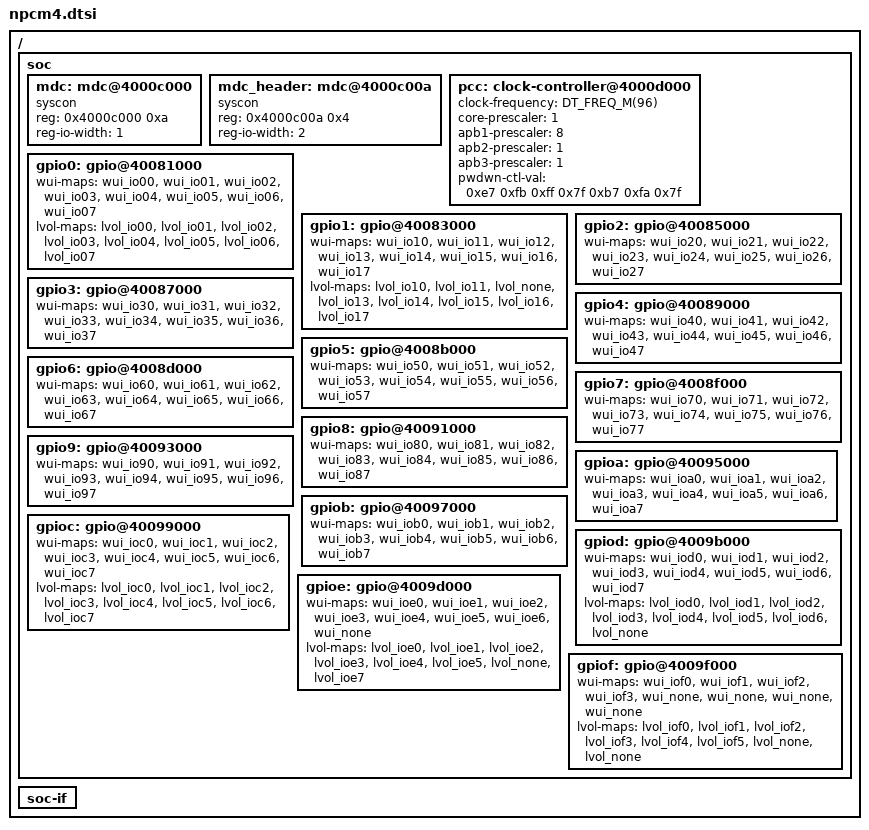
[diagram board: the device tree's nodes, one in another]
/*
 * Copyright (c) 2024 Nuvoton Technology Corporation.
 *
 * SPDX-License-Identifier: Apache-2.0
 */

/* npcm4 series pinmux mapping table */
#include "npcm4/npcm4-alts-map.dtsi"
/* npcm4 series mapping table between MIWU wui bits and source device */
#include "npcm4/npcm4-miwus-wui-map.dtsi"
/* npcm4 series mapping table between MIWU groups and interrupts */
#include "npcm4/npcm4-miwus-int-map.dtsi"
/* npcm4 series low-voltage io controls mapping table */
#include "npcm4/npcm4-lvol-ctrl-map.dtsi"

/* Device tree declarations of npcm soc family */
#include "npcm.dtsi"

#include <freq.h>

/ {
	soc {
		mdc: mdc@4000c000 {
			compatible = "syscon";
			reg = <0x4000c000 0xa>;
			reg-io-width = <1>;
		};

		mdc_header: mdc@4000c00a {
			compatible = "syscon";
			reg = <0x4000c00a 0x4>;
			reg-io-width = <2>;
		};

		pcc: clock-controller@4000d000 {
			clock-frequency = <DT_FREQ_M(96)>; /* OFMCLK runs at 96MHz */
			core-prescaler = <1>; /* CORE_CLK runs at 96MHz */
			apb1-prescaler = <8>; /* APB1_CLK runs at 12MHz */
			apb2-prescaler = <1>; /* APB2_CLK runs at 96MHz */
			apb3-prescaler = <1>; /* APB3_CLK runs at 96MHz */
			/*fiu-prescaler = <1>;  FIU_CLK runs at 96MHz */
			 /*i3c-prescaler = <1>; I3C_CLK runs at 96MHz */
			/*ram-pd-depth = <15>;  Valid bit-depth of RAM_PDn reg */
			pwdwn-ctl-val = <0xe7 /* Start with PWDWN_CTL0 */
					 0xfb /* No FIU_PD */
					 0xff
					 0x7f /* No GDMA */
					 0xb7 /* No N2JTAG/SMB_DMA */
					 0xfa /* No CCD/PSL */
					 0x7f>; /* No eSPI */
		};
		/* Wake-up input source mapping for GPIOs in npcm4 series */
		gpio0: gpio@40081000 {
			wui-maps = <&wui_io00 &wui_io01 &wui_io02 &wui_io03
				    &wui_io04 &wui_io05 &wui_io06 &wui_io07>;
			lvol-maps = <&lvol_io00 &lvol_io01 &lvol_io02 &lvol_io03
				     &lvol_io04 &lvol_io05 &lvol_io06 &lvol_io07>;
		};

		gpio1: gpio@40083000 {
			wui-maps = <&wui_io10 &wui_io11 &wui_io12 &wui_io13
				    &wui_io14 &wui_io15 &wui_io16 &wui_io17>;
			lvol-maps = <&lvol_io10 &lvol_io11 &lvol_none &lvol_io13
				     &lvol_io14 &lvol_io15 &lvol_io16 &lvol_io17>;
		};

		gpio2: gpio@40085000 {
			wui-maps = <&wui_io20 &wui_io21 &wui_io22 &wui_io23
				    &wui_io24 &wui_io25 &wui_io26 &wui_io27>;

		};

		gpio3: gpio@40087000 {
			wui-maps = <&wui_io30 &wui_io31 &wui_io32 &wui_io33
				    &wui_io34 &wui_io35 &wui_io36 &wui_io37>;

		};

		gpio4: gpio@40089000 {
			wui-maps = <&wui_io40 &wui_io41 &wui_io42 &wui_io43
				    &wui_io44 &wui_io45 &wui_io46 &wui_io47>;
		};

		gpio5: gpio@4008b000 {
			wui-maps = <&wui_io50 &wui_io51 &wui_io52 &wui_io53
				    &wui_io54 &wui_io55 &wui_io56 &wui_io57>;
		};

		gpio6: gpio@4008d000 {
			wui-maps = <&wui_io60 &wui_io61 &wui_io62 &wui_io63
				    &wui_io64 &wui_io65 &wui_io66 &wui_io67>;
		};

		gpio7: gpio@4008f000 {
			wui-maps = <&wui_io70 &wui_io71 &wui_io72 &wui_io73
				    &wui_io74 &wui_io75 &wui_io76 &wui_io77>;
		};

		gpio8: gpio@40091000 {
			wui-maps = <&wui_io80 &wui_io81 &wui_io82 &wui_io83
				    &wui_io84 &wui_io85 &wui_io86 &wui_io87>;

		};

		gpio9: gpio@40093000 {
			wui-maps = <&wui_io90 &wui_io91 &wui_io92 &wui_io93
				    &wui_io94 &wui_io95 &wui_io96 &wui_io97>;
		};

		gpioa: gpio@40095000 {
			wui-maps = <&wui_ioa0 &wui_ioa1 &wui_ioa2 &wui_ioa3
				    &wui_ioa4 &wui_ioa5 &wui_ioa6 &wui_ioa7>;

		};

		gpiob: gpio@40097000 {
			wui-maps = <&wui_iob0 &wui_iob1 &wui_iob2 &wui_iob3
				    &wui_iob4 &wui_iob5 &wui_iob6 &wui_iob7>;

		};

		gpioc: gpio@40099000 {
			wui-maps = <&wui_ioc0 &wui_ioc1 &wui_ioc2 &wui_ioc3
				    &wui_ioc4 &wui_ioc5 &wui_ioc6 &wui_ioc7>;
			lvol-maps = <&lvol_ioc0 &lvol_ioc1 &lvol_ioc2 &lvol_ioc3
				     &lvol_ioc4 &lvol_ioc5 &lvol_ioc6 &lvol_ioc7>;
		};

		gpiod: gpio@4009b000 {
			wui-maps = <&wui_iod0 &wui_iod1 &wui_iod2 &wui_iod3
				    &wui_iod4 &wui_iod5 &wui_iod6 &wui_iod7>;
			lvol-maps = <&lvol_iod0 &lvol_iod1 &lvol_iod2 &lvol_iod3
				     &lvol_iod4 &lvol_iod5 &lvol_iod6 &lvol_none>;
		};

		gpioe: gpio@4009d000 {
			wui-maps = <&wui_ioe0 &wui_ioe1 &wui_ioe2 &wui_ioe3
				    &wui_ioe4 &wui_ioe5 &wui_ioe6 &wui_none>;
			lvol-maps = <&lvol_ioe0 &lvol_ioe1 &lvol_ioe2 &lvol_ioe3
				     &lvol_ioe4 &lvol_ioe5 &lvol_none &lvol_ioe7>;
		};

		gpiof: gpio@4009f000 {
			wui-maps = <&wui_iof0 &wui_iof1 &wui_iof2 &wui_iof3
				    &wui_none &wui_none &wui_none &wui_none>;
			lvol-maps = <&lvol_iof0 &lvol_iof1 &lvol_iof2 &lvol_iof3
				     &lvol_iof4 &lvol_iof5 &lvol_none &lvol_none>;
		};
	};

	soc-if {};
};
